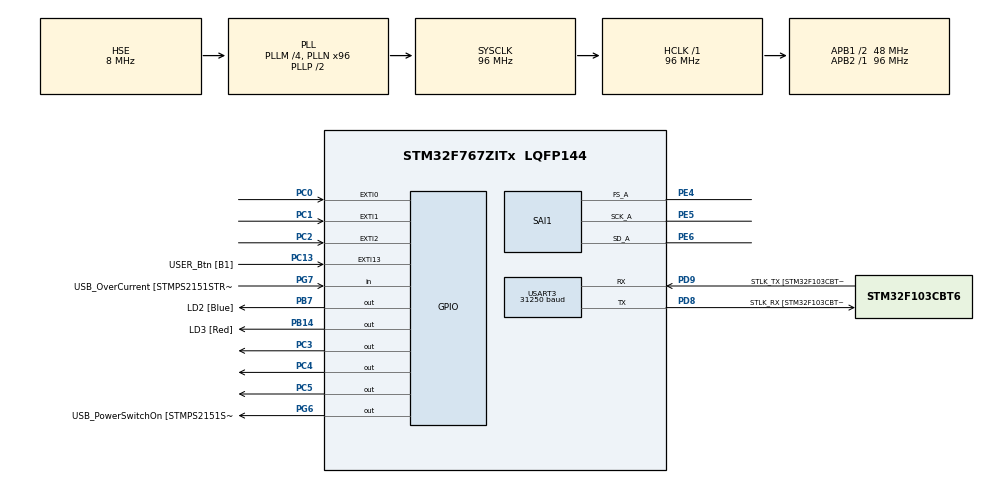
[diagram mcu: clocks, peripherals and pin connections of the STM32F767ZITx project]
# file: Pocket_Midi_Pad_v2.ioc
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Mcu.Family=STM32F7
Mcu.Name=STM32F767ZITx
Mcu.Package=LQFP144
NVIC.EXTI0_IRQn=true\:0\:0\:true\:false\:true\:true
NVIC.EXTI1_IRQn=true\:1\:0\:true\:false\:true\:true
NVIC.EXTI2_IRQn=true\:2\:0\:true\:false\:true\:true
NVIC.PriorityGroup=NVIC_PRIORITYGROUP_4
NVIC.SAI1_IRQn=true\:0\:0\:false\:false\:true\:true
NVIC.TIM2_IRQn=true\:0\:0\:false\:false\:true\:true
PA10.GPIO_Label=USB_ID
PA10.Signal=USB_OTG_FS_ID
PA11.GPIO_Label=USB_DM
PA11.Signal=USB_OTG_FS_DM
PA12.GPIO_Label=USB_DP
PA12.Signal=USB_OTG_FS_DP
PA13.GPIO_Label=TMS
PA13.Mode=Serial_Wire
PA13.Signal=SYS_JTMS-SWDIO
PA14.GPIO_Label=TCK
PA14.Mode=Serial_Wire
PA14.Signal=SYS_JTCK-SWCLK
PA8.GPIO_Label=USB_SOF [TP1]
PA8.Signal=USB_OTG_FS_SOF
PA9.GPIO_Label=USB_VBUS
PA9.Signal=USB_OTG_FS_VBUS
PB14.GPIO_Label=LD3 [Red]
PB14.Signal=GPIO_Output
PB3.GPIO_Label=SWO
PB3.Signal=SYS_JTDO-SWO
PB7.GPIO_Label=LD2 [Blue]
PB7.Signal=GPIO_Output
PC0.GPIO_PuPd=GPIO_PULLDOWN
PC0.Signal=GPXTI0
PC1.GPIO_PuPd=GPIO_PULLDOWN
PC1.Signal=GPXTI1
PC13.GPIO_Label=USER_Btn [B1]
PC13.Signal=GPXTI13
PC14/OSC32_IN.Mode=LSE-External-Oscillator
PC14/OSC32_IN.Signal=RCC_OSC32_IN
PC15/OSC32_OUT.Mode=LSE-External-Oscillator
PC15/OSC32_OUT.Signal=RCC_OSC32_OUT
PC2.GPIO_PuPd=GPIO_PULLDOWN
PC2.Signal=GPXTI2
PC3.PinState=GPIO_PIN_SET
PC3.Signal=GPIO_Output
PC4.PinState=GPIO_PIN_SET
PC4.Signal=GPIO_Output
PC5.PinState=GPIO_PIN_SET
PC5.Signal=GPIO_Output
PD8.GPIO_Label=STLK_RX [STM32F103CBT6_PA3]
PD8.Mode=Asynchronous
PD8.Signal=USART3_TX
PD9.GPIO_Label=STLK_TX [STM32F103CBT6_PA2]
PD9.Mode=Asynchronous
PD9.Signal=USART3_RX
PE4.Mode=SAI_A_Master
PE4.Signal=SAI1_FS_A
PE5.Mode=SAI_A_Master
PE5.Signal=SAI1_SCK_A
PE6.Mode=SAI_A_Master
PE6.Signal=SAI1_SD_A
PG6.GPIO_Label=USB_PowerSwitchOn [STMPS2151STR_EN]
PG6.Signal=GPIO_Output
PG7.GPIO_Label=USB_OverCurrent [STMPS2151STR_FAULT]
PG7.Signal=GPIO_Input
PH0/OSC_IN.GPIO_Label=MCO [STM32F103CBT6_PA8]
PH0/OSC_IN.Mode=HSE-External-Clock-Source
PH0/OSC_IN.Signal=RCC_OSC_IN
PH1/OSC_OUT.Mode=HSE-External-Clock-Source
PH1/OSC_OUT.Signal=RCC_OSC_OUT
ProjectManager.HeapSize=0x200
ProjectManager.StackSize=0x400
ProjectManager.TargetToolchain=SW4STM32
RCC.48MHZClocksFreq_Value=24000000
RCC.AHBFreq_Value=96000000
RCC.APB1CLKDivider=RCC_HCLK_DIV2
RCC.APB1Freq_Value=48000000
RCC.APB1TimFreq_Value=96000000
RCC.APB2Freq_Value=96000000
RCC.APB2TimFreq_Value=96000000
RCC.CortexFreq_Value=96000000
RCC.HCLKFreq_Value=96000000
RCC.HSE_VALUE=8000000
RCC.HSI_VALUE=16000000
RCC.PLLM=4
RCC.PLLMUL=RCC_PLL_MUL9
RCC.PLLN=96
RCC.PLLQ=4
RCC.PLLSAIQ=6
RCC.PLLSourceVirtual=RCC_PLLSOURCE_HSE
RCC.PRESCALERUSB=RCC_USBCLKSOURCE_PLL_DIV1_5
RCC.SYSCLKFreq_VALUE=96000000
RCC.SYSCLKSource=RCC_SYSCLKSOURCE_PLLCLK
RCC.SYSCLKSourceVirtual=RCC_SYSCLKSOURCE_PLLCLK
RCC.USBFreq_Value=48000000
RCC.VCOOutputFreq_Value=192000000
SAI1.AudioFrequency-SAI_A_Master=SAI_AUDIO_FREQUENCY_192K
SAI1.BasicDataSize-SAI_A_Master=SAI_PROTOCOL_DATASIZE_16BIT
SAI1.ErrorAudioFreq-SAI_A_Master=30.2 %
SAI1.InitProtocol-SAI_A_Master=Enable
SAI1.Instance-SAI_A_Master=SAI$Index_Block_A
SAI1.MClockEnable-SAI_A_Master=SAI_MASTERCLOCK_DISABLE
SAI1.RealAudioFreq-SAI_A_Master=250.0 KHz
SAI1.Synchro-SAI_A_Master=SAI_ASYNCHRONOUS
SAI1.VirtualMode-SAI_A_Master=VM_MASTER
SAI1.VirtualProtocol-SAI_A_BASIC=VM_BASIC_PROTOCOL
TIM2.AutoReloadPreload=TIM_AUTORELOAD_PRELOAD_ENABLE
TIM2.Period=1000
TIM2.Prescaler=96
TIM2.TIM_MasterOutputTrigger=TIM_TRGO_UPDATE
USART3.BaudRate=31250
USART3.VirtualMode-Asynchronous=VM_ASYNC
USART3.WordLength=WORDLENGTH_8B
VP_SAI1_VP_$IpInstance_SAIA_SAI_BASIC.Mode=SAI_A_BASIC
VP_TIM2_VS_ClockSourceINT.Mode=Internal
VP_TIM2_VS_OPM.Mode=OPM_bit
board=NUCLEO-F767ZI

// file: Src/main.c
/**
  ******************************************************************************
  * @file           : main.c
  * @brief          : Main program body
  ******************************************************************************
  ** This notice applies to any and all portions of this file
  * that are not between comment pairs USER CODE BEGIN and
  * USER CODE END. Other portions of this file, whether
  * inserted by the user or by software development tools
  * are owned by their respective copyright owners.
  *
  * COPYRIGHT(c) 2018 STMicroelectronics
  *
  * Redistribution and use in source and binary forms, with or without modification,
  * are permitted provided that the following conditions are met:
  *   1. Redistributions of source code must retain the above copyright notice,
  *      this list of conditions and the following disclaimer.
  *   2. Redistributions in binary form must reproduce the above copyright notice,
  *      this list of conditions and the following disclaimer in the documentation
  *      and/or other materials provided with the distribution.
  *   3. Neither the name of STMicroelectronics nor the names of its contributors
  *      may be used to endorse or promote products derived from this software
  *      without specific prior written permission.
  *
  * THIS SOFTWARE IS PROVIDED BY THE COPYRIGHT HOLDERS AND CONTRIBUTORS "AS IS"
  * AND ANY EXPRESS OR IMPLIED WARRANTIES, INCLUDING, BUT NOT LIMITED TO, THE
  * IMPLIED WARRANTIES OF MERCHANTABILITY AND FITNESS FOR A PARTICULAR PURPOSE ARE
  * DISCLAIMED. IN NO EVENT SHALL THE COPYRIGHT HOLDER OR CONTRIBUTORS BE LIABLE
  * FOR ANY DIRECT, INDIRECT, INCIDENTAL, SPECIAL, EXEMPLARY, OR CONSEQUENTIAL
  * DAMAGES (INCLUDING, BUT NOT LIMITED TO, PROCUREMENT OF SUBSTITUTE GOODS OR
  * SERVICES; LOSS OF USE, DATA, OR PROFITS; OR BUSINESS INTERRUPTION) HOWEVER
  * CAUSED AND ON ANY THEORY OF LIABILITY, WHETHER IN CONTRACT, STRICT LIABILITY,
  * OR TORT (INCLUDING NEGLIGENCE OR OTHERWISE) ARISING IN ANY WAY OUT OF THE USE
  * OF THIS SOFTWARE, EVEN IF ADVISED OF THE POSSIBILITY OF SUCH DAMAGE.
  *
  ******************************************************************************
  */
#include "main.h"
#include "stm32f7xx_hal.h"

/* USER CODE BEGIN Includes */
#include "defines.h"

bool gateKeeper = __locked;
/* USER CODE END Includes */

SAI_HandleTypeDef hsai_BlockA1;

TIM_HandleTypeDef htim2;

UART_HandleTypeDef huart3;

/* USER CODE BEGIN PV */
/* Private variables ---------------------------------------------------------*/
//uint8_t dummy;
/* USER CODE END PV */

void SystemClock_Config(void);
static void MX_GPIO_Init(void);
static void MX_USART3_UART_Init(void);
static void MX_TIM2_Init(void);
static void MX_SAI1_Init(void);

/* USER CODE BEGIN PFP */
/* Private function prototypes -----------------------------------------------*/

/* USER CODE END PFP */

int main(void)
{

  /* MCU Configuration----------------------------------------------------------*/

  /* Reset of all peripherals, Initializes the Flash interface and the Systick. */
  HAL_Init();

  /* Configure the system clock */
  SystemClock_Config();

  /* Initialize all configured peripherals */
  MX_GPIO_Init();
  MX_USART3_UART_Init();
  MX_TIM2_Init();
  MX_SAI1_Init();
  /* USER CODE BEGIN 2 */
  Transmit(0x90); 					//set status byte to note on
  HAL_TIM_Base_Start_IT(&htim2);	//start de-bounce timer
  /* USER CODE END 2 */

  /* Infinite loop */
  while (1)
  {

  }

}

void SystemClock_Config(void)
{

  RCC_OscInitTypeDef RCC_OscInitStruct;
  RCC_ClkInitTypeDef RCC_ClkInitStruct;
  RCC_PeriphCLKInitTypeDef PeriphClkInitStruct;

    /**Configure the main internal regulator output voltage
    */
  __HAL_RCC_PWR_CLK_ENABLE();

  __HAL_PWR_VOLTAGESCALING_CONFIG(PWR_REGULATOR_VOLTAGE_SCALE3);

    /**Initializes the CPU, AHB and APB busses clocks
    */
  RCC_OscInitStruct.OscillatorType = RCC_OSCILLATORTYPE_HSE;
  RCC_OscInitStruct.HSEState = RCC_HSE_BYPASS;
  RCC_OscInitStruct.PLL.PLLState = RCC_PLL_ON;
  RCC_OscInitStruct.PLL.PLLSource = RCC_PLLSOURCE_HSE;
  RCC_OscInitStruct.PLL.PLLM = 4;
  RCC_OscInitStruct.PLL.PLLN = 96;
  RCC_OscInitStruct.PLL.PLLP = RCC_PLLP_DIV2;
  RCC_OscInitStruct.PLL.PLLQ = 4;
  if (HAL_RCC_OscConfig(&RCC_OscInitStruct) != HAL_OK)
  {
    _Error_Handler(__FILE__, __LINE__);
  }

    /**Activate the Over-Drive mode
    */
  if (HAL_PWREx_EnableOverDrive() != HAL_OK)
  {
    _Error_Handler(__FILE__, __LINE__);
  }

    /**Initializes the CPU, AHB and APB busses clocks
    */
  RCC_ClkInitStruct.ClockType = RCC_CLOCKTYPE_HCLK|RCC_CLOCKTYPE_SYSCLK
                              |RCC_CLOCKTYPE_PCLK1|RCC_CLOCKTYPE_PCLK2;
  RCC_ClkInitStruct.SYSCLKSource = RCC_SYSCLKSOURCE_PLLCLK;
  RCC_ClkInitStruct.AHBCLKDivider = RCC_SYSCLK_DIV1;
  RCC_ClkInitStruct.APB1CLKDivider = RCC_HCLK_DIV2;
  RCC_ClkInitStruct.APB2CLKDivider = RCC_HCLK_DIV1;

  if (HAL_RCC_ClockConfig(&RCC_ClkInitStruct, FLASH_LATENCY_3) != HAL_OK)
  {
    _Error_Handler(__FILE__, __LINE__);
  }

  PeriphClkInitStruct.PeriphClockSelection = RCC_PERIPHCLK_USART3|RCC_PERIPHCLK_SAI1;
  PeriphClkInitStruct.PLLSAI.PLLSAIN = 192;
  PeriphClkInitStruct.PLLSAI.PLLSAIR = 2;
  PeriphClkInitStruct.PLLSAI.PLLSAIQ = 6;
  PeriphClkInitStruct.PLLSAI.PLLSAIP = RCC_PLLSAIP_DIV2;
  PeriphClkInitStruct.PLLSAIDivQ = 1;
  PeriphClkInitStruct.PLLSAIDivR = RCC_PLLSAIDIVR_2;
  PeriphClkInitStruct.Sai1ClockSelection = RCC_SAI1CLKSOURCE_PLLSAI;
  PeriphClkInitStruct.Usart3ClockSelection = RCC_USART3CLKSOURCE_PCLK1;
  if (HAL_RCCEx_PeriphCLKConfig(&PeriphClkInitStruct) != HAL_OK)
  {
    _Error_Handler(__FILE__, __LINE__);
  }

    /**Configure the Systick interrupt time
    */
  HAL_SYSTICK_Config(HAL_RCC_GetHCLKFreq()/1000);

    /**Configure the Systick
    */
  HAL_SYSTICK_CLKSourceConfig(SYSTICK_CLKSOURCE_HCLK);

  /* SysTick_IRQn interrupt configuration */
  HAL_NVIC_SetPriority(SysTick_IRQn, 0, 0);
}

/* SAI1 init function */
static void MX_SAI1_Init(void)
{

  hsai_BlockA1.Instance = SAI1_Block_A;
  hsai_BlockA1.Init.AudioMode = SAI_MODEMASTER_TX;
  hsai_BlockA1.Init.Synchro = SAI_ASYNCHRONOUS;
  hsai_BlockA1.Init.OutputDrive = SAI_OUTPUTDRIVE_DISABLE;
  hsai_BlockA1.Init.NoDivider = SAI_MASTERDIVIDER_ENABLE;
  hsai_BlockA1.Init.FIFOThreshold = SAI_FIFOTHRESHOLD_EMPTY;
  hsai_BlockA1.Init.AudioFrequency = SAI_AUDIO_FREQUENCY_192K;
  hsai_BlockA1.Init.SynchroExt = SAI_SYNCEXT_DISABLE;
  hsai_BlockA1.Init.MonoStereoMode = SAI_STEREOMODE;
  hsai_BlockA1.Init.CompandingMode = SAI_NOCOMPANDING;
  hsai_BlockA1.Init.TriState = SAI_OUTPUT_NOTRELEASED;
  if (HAL_SAI_InitProtocol(&hsai_BlockA1, SAI_I2S_STANDARD, SAI_PROTOCOL_DATASIZE_16BIT, 2) != HAL_OK)
  {
    _Error_Handler(__FILE__, __LINE__);
  }

}

/* TIM2 init function */
static void MX_TIM2_Init(void)
{

  TIM_ClockConfigTypeDef sClockSourceConfig;
  TIM_MasterConfigTypeDef sMasterConfig;

  htim2.Instance = TIM2;
  htim2.Init.Prescaler = 96;
  htim2.Init.CounterMode = TIM_COUNTERMODE_UP;
  htim2.Init.Period = 1000;
  htim2.Init.ClockDivision = TIM_CLOCKDIVISION_DIV1;
  htim2.Init.AutoReloadPreload = TIM_AUTORELOAD_PRELOAD_ENABLE;
  if (HAL_TIM_Base_Init(&htim2) != HAL_OK)
  {
    _Error_Handler(__FILE__, __LINE__);
  }

  sClockSourceConfig.ClockSource = TIM_CLOCKSOURCE_INTERNAL;
  if (HAL_TIM_ConfigClockSource(&htim2, &sClockSourceConfig) != HAL_OK)
  {
    _Error_Handler(__FILE__, __LINE__);
  }

  if (HAL_TIM_OnePulse_Init(&htim2, TIM_OPMODE_SINGLE) != HAL_OK)
  {
    _Error_Handler(__FILE__, __LINE__);
  }

  sMasterConfig.MasterOutputTrigger = TIM_TRGO_UPDATE;
  sMasterConfig.MasterSlaveMode = TIM_MASTERSLAVEMODE_DISABLE;
  if (HAL_TIMEx_MasterConfigSynchronization(&htim2, &sMasterConfig) != HAL_OK)
  {
    _Error_Handler(__FILE__, __LINE__);
  }

}

/* USART3 init function */
static void MX_USART3_UART_Init(void)
{

  huart3.Instance = USART3;
  huart3.Init.BaudRate = 31250;
  huart3.Init.WordLength = UART_WORDLENGTH_8B;
  huart3.Init.StopBits = UART_STOPBITS_1;
  huart3.Init.Parity = UART_PARITY_NONE;
  huart3.Init.Mode = UART_MODE_TX_RX;
  huart3.Init.HwFlowCtl = UART_HWCONTROL_NONE;
  huart3.Init.OverSampling = UART_OVERSAMPLING_16;
  huart3.Init.OneBitSampling = UART_ONE_BIT_SAMPLE_DISABLE;
  huart3.AdvancedInit.AdvFeatureInit = UART_ADVFEATURE_NO_INIT;
  if (HAL_UART_Init(&huart3) != HAL_OK)
  {
    _Error_Handler(__FILE__, __LINE__);
  }

}

/** Configure pins as
        * Analog
        * Input
        * Output
        * EVENT_OUT
        * EXTI
     PA8   ------> USB_OTG_FS_SOF
     PA9   ------> USB_OTG_FS_VBUS
     PA10   ------> USB_OTG_FS_ID
     PA11   ------> USB_OTG_FS_DM
     PA12   ------> USB_OTG_FS_DP
*/
static void MX_GPIO_Init(void)
{

  GPIO_InitTypeDef GPIO_InitStruct;

  /* GPIO Ports Clock Enable */
  __HAL_RCC_GPIOE_CLK_ENABLE();
  __HAL_RCC_GPIOC_CLK_ENABLE();
  __HAL_RCC_GPIOH_CLK_ENABLE();
  __HAL_RCC_GPIOB_CLK_ENABLE();
  __HAL_RCC_GPIOD_CLK_ENABLE();
  __HAL_RCC_GPIOG_CLK_ENABLE();
  __HAL_RCC_GPIOA_CLK_ENABLE();

  /*Configure GPIO pin Output Level */
  HAL_GPIO_WritePin(GPIOC, GPIO_PIN_3|GPIO_PIN_4|GPIO_PIN_5, GPIO_PIN_SET);

  /*Configure GPIO pin Output Level */
  HAL_GPIO_WritePin(GPIOB, LD3_Pin|LD2_Pin, GPIO_PIN_RESET);

  /*Configure GPIO pin Output Level */
  HAL_GPIO_WritePin(USB_PowerSwitchOn_GPIO_Port, USB_PowerSwitchOn_Pin, GPIO_PIN_RESET);

  /*Configure GPIO pin : USER_Btn_Pin */
  GPIO_InitStruct.Pin = USER_Btn_Pin;
  GPIO_InitStruct.Mode = GPIO_MODE_IT_RISING;
  GPIO_InitStruct.Pull = GPIO_NOPULL;
  HAL_GPIO_Init(USER_Btn_GPIO_Port, &GPIO_InitStruct);

  /*Configure GPIO pins : PC0 PC1 PC2 */
  GPIO_InitStruct.Pin = GPIO_PIN_0|GPIO_PIN_1|GPIO_PIN_2;
  GPIO_InitStruct.Mode = GPIO_MODE_IT_RISING;
  GPIO_InitStruct.Pull = GPIO_PULLDOWN;
  HAL_GPIO_Init(GPIOC, &GPIO_InitStruct);

  /*Configure GPIO pins : PC3 PC4 PC5 */
  GPIO_InitStruct.Pin = GPIO_PIN_3|GPIO_PIN_4|GPIO_PIN_5;
  GPIO_InitStruct.Mode = GPIO_MODE_OUTPUT_PP;
  GPIO_InitStruct.Pull = GPIO_NOPULL;
  GPIO_InitStruct.Speed = GPIO_SPEED_FREQ_LOW;
  HAL_GPIO_Init(GPIOC, &GPIO_InitStruct);

  /*Configure GPIO pins : LD3_Pin LD2_Pin */
  GPIO_InitStruct.Pin = LD3_Pin|LD2_Pin;
  GPIO_InitStruct.Mode = GPIO_MODE_OUTPUT_PP;
  GPIO_InitStruct.Pull = GPIO_NOPULL;
  GPIO_InitStruct.Speed = GPIO_SPEED_FREQ_LOW;
  HAL_GPIO_Init(GPIOB, &GPIO_InitStruct);

  /*Configure GPIO pin : USB_PowerSwitchOn_Pin */
  GPIO_InitStruct.Pin = USB_PowerSwitchOn_Pin;
  GPIO_InitStruct.Mode = GPIO_MODE_OUTPUT_PP;
  GPIO_InitStruct.Pull = GPIO_NOPULL;
  GPIO_InitStruct.Speed = GPIO_SPEED_FREQ_LOW;
  HAL_GPIO_Init(USB_PowerSwitchOn_GPIO_Port, &GPIO_InitStruct);

  /*Configure GPIO pin : USB_OverCurrent_Pin */
  GPIO_InitStruct.Pin = USB_OverCurrent_Pin;
  GPIO_InitStruct.Mode = GPIO_MODE_INPUT;
  GPIO_InitStruct.Pull = GPIO_NOPULL;
  HAL_GPIO_Init(USB_OverCurrent_GPIO_Port, &GPIO_InitStruct);

  /*Configure GPIO pins : USB_SOF_Pin USB_ID_Pin USB_DM_Pin USB_DP_Pin */
  GPIO_InitStruct.Pin = USB_SOF_Pin|USB_ID_Pin|USB_DM_Pin|USB_DP_Pin;
  GPIO_InitStruct.Mode = GPIO_MODE_AF_PP;
  GPIO_InitStruct.Pull = GPIO_NOPULL;
  GPIO_InitStruct.Speed = GPIO_SPEED_FREQ_VERY_HIGH;
  GPIO_InitStruct.Alternate = GPIO_AF10_OTG_FS;
  HAL_GPIO_Init(GPIOA, &GPIO_InitStruct);

  /*Configure GPIO pin : USB_VBUS_Pin */
  GPIO_InitStruct.Pin = USB_VBUS_Pin;
  GPIO_InitStruct.Mode = GPIO_MODE_INPUT;
  GPIO_InitStruct.Pull = GPIO_NOPULL;
  HAL_GPIO_Init(USB_VBUS_GPIO_Port, &GPIO_InitStruct);

  /* EXTI interrupt init*/
  HAL_NVIC_SetPriority(EXTI0_IRQn, 0, 0);
  HAL_NVIC_EnableIRQ(EXTI0_IRQn);

  HAL_NVIC_SetPriority(EXTI1_IRQn, 1, 0);
  HAL_NVIC_EnableIRQ(EXTI1_IRQn);

  HAL_NVIC_SetPriority(EXTI2_IRQn, 2, 0);
  HAL_NVIC_EnableIRQ(EXTI2_IRQn);

}

/* USER CODE BEGIN 4 */

/**
  * @brief Function to transmit single UART messages
  * 	   > Primarily used for the status byte of the MIDI protocol
  * @retval None
  */
void Transmit(uint8_t data)
{
	HAL_UART_Transmit(&huart3, &data, 1, 100);
}

/**
  * @brief Function to transmit MIDI Note Value and Velocity Value
  * 	   > Assumes status byte is set to 0x9n
  * @retval None
  */
void TransmitMidi(uint8_t Note, uint8_t Velocity)
{
	uint8_t data[2] = {Note, Velocity};

	HAL_UART_Transmit(&huart3, &data, 2, 100);

}
/* USER CODE END 4 */

void _Error_Handler(char *file, int line)
{
  while(1)
  {
  }
}

/************************ (C) COPYRIGHT STMicroelectronics *****END OF FILE****/
